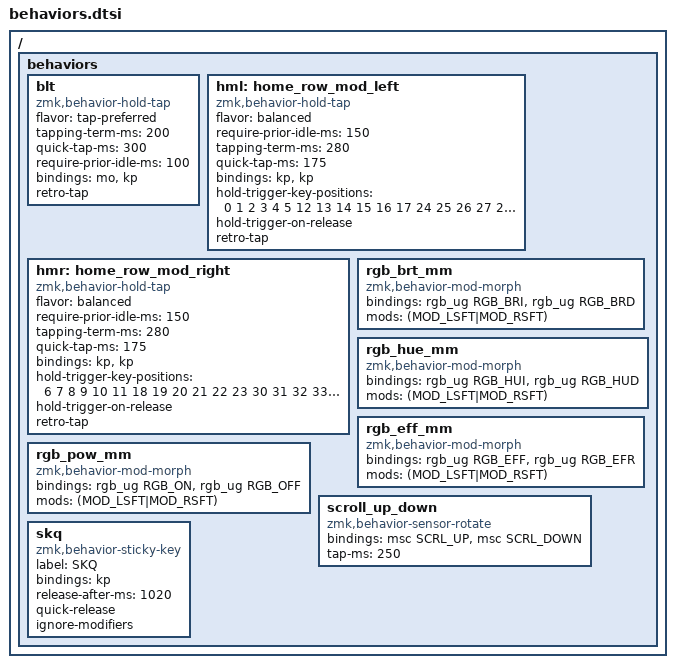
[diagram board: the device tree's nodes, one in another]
/ {
    behaviors {
        blt: blt {
            compatible = "zmk,behavior-hold-tap";
            #binding-cells = <2>;
            flavor = "tap-preferred";
            tapping-term-ms = <200>;
            quick-tap-ms = <300>;
            require-prior-idle-ms = <100>;
            bindings = <&mo>, <&kp>;
            retro-tap;
        };

        hml: home_row_mod_left {
            compatible = "zmk,behavior-hold-tap";
            #binding-cells = <2>;
            flavor = "balanced";
            require-prior-idle-ms = <150>;
            tapping-term-ms = <280>;
            quick-tap-ms = <175>;
            bindings = <&kp>, <&kp>;
            hold-trigger-key-positions = <0 1 2 3 4 5 12 13 14 15 16 17 24 25 26 27 28 29 36 37 38 39 40 41 48 49 50 53 54>;
            hold-trigger-on-release;
            retro-tap;
        };

        hmr: home_row_mod_right {
            compatible = "zmk,behavior-hold-tap";
            #binding-cells = <2>;
            flavor = "balanced";
            require-prior-idle-ms = <150>;
            tapping-term-ms = <280>;
            quick-tap-ms = <175>;
            bindings = <&kp>, <&kp>;
            hold-trigger-key-positions = <6 7 8 9 10 11 18 19 20 21 22 23 30 31 32 33 34 35 42 43 44 45 46 47 51 52 55>;
            hold-trigger-on-release;
            retro-tap;
        };

        rgb_brt_mm: rgb_brt_mm {
            compatible = "zmk,behavior-mod-morph";
            #binding-cells = <0>;
            bindings = <&rgb_ug RGB_BRI>, <&rgb_ug RGB_BRD>;
            mods = <(MOD_LSFT|MOD_RSFT)>;
        };

        rgb_hue_mm: rgb_hue_mm {
            compatible = "zmk,behavior-mod-morph";
            #binding-cells = <0>;
            bindings = <&rgb_ug RGB_HUI>, <&rgb_ug RGB_HUD>;
            mods = <(MOD_LSFT|MOD_RSFT)>;
        };

        rgb_eff_mm: rgb_eff_mm {
            compatible = "zmk,behavior-mod-morph";
            #binding-cells = <0>;
            bindings = <&rgb_ug RGB_EFF>, <&rgb_ug RGB_EFR>;
            mods = <(MOD_LSFT|MOD_RSFT)>;
        };

        rgb_pow_mm: rgb_pow_mm {
            compatible = "zmk,behavior-mod-morph";
            #binding-cells = <0>;
            bindings = <&rgb_ug RGB_ON>, <&rgb_ug RGB_OFF>;
            mods = <(MOD_LSFT|MOD_RSFT)>;
        };

        scroll_up_down: scroll_up_down {
            compatible = "zmk,behavior-sensor-rotate";
            #sensor-binding-cells = <0>;
            bindings = <&msc SCRL_UP>, <&msc SCRL_DOWN>;
            tap-ms = <250>;
        };

        skq: skq {
            compatible = "zmk,behavior-sticky-key";
            label = "SKQ";
            bindings = <&kp>;
            #binding-cells = <1>;
            release-after-ms = <1020>;
            quick-release;
            ignore-modifiers;
        };
    };
};
